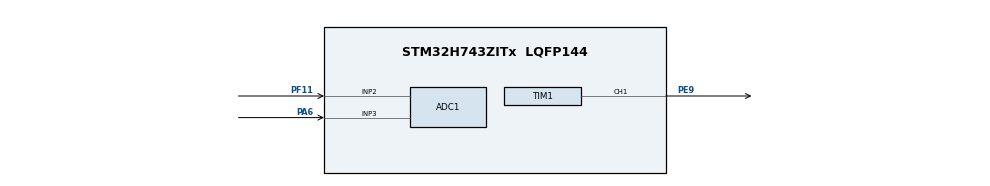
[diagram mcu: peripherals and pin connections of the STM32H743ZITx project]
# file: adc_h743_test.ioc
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ADC1.Channel-0\#ChannelRegularConversion=ADC_CHANNEL_2
ADC1.Channel-1\#ChannelRegularConversion=ADC_CHANNEL_3
ADC1.ContinuousConvMode=ENABLE
ADC1.ConversionDataManagement=ADC_CONVERSIONDATA_DMA_CIRCULAR
ADC1.EOCSelection=ADC_EOC_SEQ_CONV
ADC1.NbrOfConversion=2
ADC1.NbrOfConversionFlag=1
ADC1.OffsetNumber-0\#ChannelRegularConversion=ADC_OFFSET_NONE
ADC1.OffsetNumber-1\#ChannelRegularConversion=ADC_OFFSET_NONE
ADC1.OffsetSignedSaturation-0\#ChannelRegularConversion=DISABLE
ADC1.OffsetSignedSaturation-1\#ChannelRegularConversion=DISABLE
ADC1.Overrun=ADC_OVR_DATA_OVERWRITTEN
ADC1.OversamplingMode=ENABLE
ADC1.Rank-0\#ChannelRegularConversion=1
ADC1.Rank-1\#ChannelRegularConversion=2
ADC1.Ratio=32
ADC1.RightBitShift=ADC_RIGHTBITSHIFT_5
ADC1.SamplingTime-0\#ChannelRegularConversion=ADC_SAMPLETIME_8CYCLES_5
ADC1.SamplingTime-1\#ChannelRegularConversion=ADC_SAMPLETIME_8CYCLES_5
ADC1.master=1
Dma.ADC1.0.Direction=DMA_PERIPH_TO_MEMORY
Dma.ADC1.0.EventEnable=DISABLE
Dma.ADC1.0.FIFOMode=DMA_FIFOMODE_DISABLE
Dma.ADC1.0.Instance=DMA1_Stream1
Dma.ADC1.0.MemDataAlignment=DMA_MDATAALIGN_WORD
Dma.ADC1.0.MemInc=DMA_MINC_ENABLE
Dma.ADC1.0.Mode=DMA_CIRCULAR
Dma.ADC1.0.PeriphDataAlignment=DMA_PDATAALIGN_WORD
Dma.ADC1.0.PeriphInc=DMA_PINC_DISABLE
Dma.ADC1.0.Polarity=HAL_DMAMUX_REQ_GEN_RISING
Dma.ADC1.0.Priority=DMA_PRIORITY_VERY_HIGH
Dma.ADC1.0.RequestNumber=1
Dma.ADC1.0.SignalID=NONE
Dma.ADC1.0.SyncEnable=DISABLE
Dma.ADC1.0.SyncPolarity=HAL_DMAMUX_SYNC_NO_EVENT
Dma.ADC1.0.SyncRequestNumber=1
Dma.ADC1.0.SyncSignalID=NONE
Dma.Request0=ADC1
Mcu.Family=STM32H7
Mcu.Name=STM32H743ZITx
Mcu.Package=LQFP144
NVIC.DMA1_Stream1_IRQn=true\:0\:0\:false\:false\:true\:false\:true
NVIC.PriorityGroup=NVIC_PRIORITYGROUP_4
PA6.Signal=ADCx_INP3
PE9.Signal=S_TIM1_CH1
PF11.Mode=IN2-Single-Ended
PF11.Signal=ADC1_INP2
ProjectManager.HeapSize=0x200
ProjectManager.StackSize=0x400
ProjectManager.TargetToolchain=STM32CubeIDE
RCC.ADCFreq_Value=37500000
RCC.APB1Freq_Value=64000000
RCC.APB2Freq_Value=64000000
RCC.APB3Freq_Value=64000000
RCC.APB4Freq_Value=64000000
RCC.CortexFreq_Value=64000000
RCC.DIVM2=4
RCC.DIVN2=9
RCC.DIVP2=4
RCC.HCLKFreq_Value=64000000
RCC.PLL2FRACN=3072
RCC.SYSCLKFreq_VALUE=64000000
RCC.USBFreq_Value=129000000
SH.ADCx_INP3.0=ADC1_INP3,IN3-Single-Ended
SH.S_TIM1_CH1.0=TIM1_CH1,PWM Generation1 CH1
TIM1.Channel-PWM\ Generation1\ CH1=TIM_CHANNEL_1
TIM1.Period=64000
TIM1.Prescaler=1
TIM1.Pulse-PWM\ Generation1\ CH1=32000
VP_TIM1_VS_ClockSourceINT.Mode=Internal
board=custom

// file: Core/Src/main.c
/* USER CODE BEGIN Header */
/**
 ******************************************************************************
 * @file           : main.c
 * @brief          : Main program body
 ******************************************************************************
 * @attention
 *
 * <h2><center>&copy; Copyright (c) 2022 STMicroelectronics.
 * All rights reserved.</center></h2>
 *
 * This software component is licensed by ST under BSD 3-Clause license,
 * the "License"; You may not use this file except in compliance with the
 * License. You may obtain a copy of the License at:
 *                        opensource.org/licenses/BSD-3-Clause
 *
 ******************************************************************************
 */
/* USER CODE END Header */
#include "main.h"

ADC_HandleTypeDef hadc1;
DMA_HandleTypeDef hdma_adc1;

TIM_HandleTypeDef htim1;

/* USER CODE BEGIN PV */
uint32_t Value [2];
uint32_t Signal = 0;
/* USER CODE END PV */

void SystemClock_Config(void);
static void MX_GPIO_Init(void);
static void MX_TIM1_Init(void);
static void MX_DMA_Init(void);
static void MX_ADC1_Init(void);

int main(void)
{

  /* MCU Configuration--------------------------------------------------------*/

  /* Reset of all peripherals, Initializes the Flash interface and the Systick. */
  HAL_Init();

  /* Configure the system clock */
  SystemClock_Config();

  /* Initialize all configured peripherals */
  MX_GPIO_Init();
  MX_TIM1_Init();
  MX_DMA_Init();
  MX_ADC1_Init();
  /* USER CODE BEGIN 2 */
	HAL_TIM_PWM_Start(&htim1,TIM_CHANNEL_1);
	HAL_ADC_Start_DMA( &hadc1, (uint32_t *) Value, 2);
	HAL_ADCEx_Calibration_Start( &hadc1,   ADC_CALIB_OFFSET,  ADC_SINGLE_ENDED);
  /* USER CODE END 2 */

  /* Infinite loop */
	while (1)
	{

    /* USER CODE BEGIN 3 */

		Signal = Value [0];

	}
  /* USER CODE END 3 */
}

void SystemClock_Config(void)
{
  RCC_OscInitTypeDef RCC_OscInitStruct = {0};
  RCC_ClkInitTypeDef RCC_ClkInitStruct = {0};

  /** Supply configuration update enable
  */
  HAL_PWREx_ConfigSupply(PWR_LDO_SUPPLY);
  /** Configure the main internal regulator output voltage
  */
  __HAL_PWR_VOLTAGESCALING_CONFIG(PWR_REGULATOR_VOLTAGE_SCALE3);

  while(!__HAL_PWR_GET_FLAG(PWR_FLAG_VOSRDY)) {}
  /** Macro to configure the PLL clock source
  */
  __HAL_RCC_PLL_PLLSOURCE_CONFIG(RCC_PLLSOURCE_HSI);
  /** Initializes the RCC Oscillators according to the specified parameters
  * in the RCC_OscInitTypeDef structure.
  */
  RCC_OscInitStruct.OscillatorType = RCC_OSCILLATORTYPE_HSI;
  RCC_OscInitStruct.HSIState = RCC_HSI_DIV1;
  RCC_OscInitStruct.HSICalibrationValue = RCC_HSICALIBRATION_DEFAULT;
  RCC_OscInitStruct.PLL.PLLState = RCC_PLL_NONE;
  RCC_OscInitStruct.PLL.PLLSource = RCC_PLLSOURCE_HSI;
  if (HAL_RCC_OscConfig(&RCC_OscInitStruct) != HAL_OK)
  {
    Error_Handler();
  }
  /** Initializes the CPU, AHB and APB buses clocks
  */
  RCC_ClkInitStruct.ClockType = RCC_CLOCKTYPE_HCLK|RCC_CLOCKTYPE_SYSCLK
                              |RCC_CLOCKTYPE_PCLK1|RCC_CLOCKTYPE_PCLK2
                              |RCC_CLOCKTYPE_D3PCLK1|RCC_CLOCKTYPE_D1PCLK1;
  RCC_ClkInitStruct.SYSCLKSource = RCC_SYSCLKSOURCE_HSI;
  RCC_ClkInitStruct.SYSCLKDivider = RCC_SYSCLK_DIV1;
  RCC_ClkInitStruct.AHBCLKDivider = RCC_HCLK_DIV1;
  RCC_ClkInitStruct.APB3CLKDivider = RCC_APB3_DIV1;
  RCC_ClkInitStruct.APB1CLKDivider = RCC_APB1_DIV1;
  RCC_ClkInitStruct.APB2CLKDivider = RCC_APB2_DIV1;
  RCC_ClkInitStruct.APB4CLKDivider = RCC_APB4_DIV1;

  if (HAL_RCC_ClockConfig(&RCC_ClkInitStruct, FLASH_LATENCY_1) != HAL_OK)
  {
    Error_Handler();
  }
}

static void MX_ADC1_Init(void)
{

  ADC_MultiModeTypeDef multimode = {0};
  ADC_ChannelConfTypeDef sConfig = {0};

  /** Common config
  */
  hadc1.Instance = ADC1;
  hadc1.Init.ClockPrescaler = ADC_CLOCK_ASYNC_DIV1;
  hadc1.Init.Resolution = ADC_RESOLUTION_16B;
  hadc1.Init.ScanConvMode = ADC_SCAN_ENABLE;
  hadc1.Init.EOCSelection = ADC_EOC_SEQ_CONV;
  hadc1.Init.LowPowerAutoWait = DISABLE;
  hadc1.Init.ContinuousConvMode = ENABLE;
  hadc1.Init.NbrOfConversion = 2;
  hadc1.Init.DiscontinuousConvMode = DISABLE;
  hadc1.Init.ExternalTrigConv = ADC_SOFTWARE_START;
  hadc1.Init.ExternalTrigConvEdge = ADC_EXTERNALTRIGCONVEDGE_NONE;
  hadc1.Init.ConversionDataManagement = ADC_CONVERSIONDATA_DMA_CIRCULAR;
  hadc1.Init.Overrun = ADC_OVR_DATA_OVERWRITTEN;
  hadc1.Init.LeftBitShift = ADC_LEFTBITSHIFT_NONE;
  hadc1.Init.OversamplingMode = ENABLE;
  hadc1.Init.Oversampling.Ratio = 32;
  hadc1.Init.Oversampling.RightBitShift = ADC_RIGHTBITSHIFT_5;
  hadc1.Init.Oversampling.TriggeredMode = ADC_TRIGGEREDMODE_SINGLE_TRIGGER;
  hadc1.Init.Oversampling.OversamplingStopReset = ADC_REGOVERSAMPLING_CONTINUED_MODE;
  if (HAL_ADC_Init(&hadc1) != HAL_OK)
  {
    Error_Handler();
  }
  /** Configure the ADC multi-mode
  */
  multimode.Mode = ADC_MODE_INDEPENDENT;
  if (HAL_ADCEx_MultiModeConfigChannel(&hadc1, &multimode) != HAL_OK)
  {
    Error_Handler();
  }
  /** Configure Regular Channel
  */
  sConfig.Channel = ADC_CHANNEL_2;
  sConfig.Rank = ADC_REGULAR_RANK_1;
  sConfig.SamplingTime = ADC_SAMPLETIME_8CYCLES_5;
  sConfig.SingleDiff = ADC_SINGLE_ENDED;
  sConfig.OffsetNumber = ADC_OFFSET_NONE;
  sConfig.Offset = 0;
  sConfig.OffsetSignedSaturation = DISABLE;
  if (HAL_ADC_ConfigChannel(&hadc1, &sConfig) != HAL_OK)
  {
    Error_Handler();
  }
  /** Configure Regular Channel
  */
  sConfig.Channel = ADC_CHANNEL_3;
  sConfig.Rank = ADC_REGULAR_RANK_2;
  if (HAL_ADC_ConfigChannel(&hadc1, &sConfig) != HAL_OK)
  {
    Error_Handler();
  }

}

static void MX_TIM1_Init(void)
{

  TIM_ClockConfigTypeDef sClockSourceConfig = {0};
  TIM_MasterConfigTypeDef sMasterConfig = {0};
  TIM_OC_InitTypeDef sConfigOC = {0};
  TIM_BreakDeadTimeConfigTypeDef sBreakDeadTimeConfig = {0};

  htim1.Instance = TIM1;
  htim1.Init.Prescaler = 1;
  htim1.Init.CounterMode = TIM_COUNTERMODE_UP;
  htim1.Init.Period = 64000;
  htim1.Init.ClockDivision = TIM_CLOCKDIVISION_DIV1;
  htim1.Init.RepetitionCounter = 0;
  htim1.Init.AutoReloadPreload = TIM_AUTORELOAD_PRELOAD_DISABLE;
  if (HAL_TIM_Base_Init(&htim1) != HAL_OK)
  {
    Error_Handler();
  }
  sClockSourceConfig.ClockSource = TIM_CLOCKSOURCE_INTERNAL;
  if (HAL_TIM_ConfigClockSource(&htim1, &sClockSourceConfig) != HAL_OK)
  {
    Error_Handler();
  }
  if (HAL_TIM_PWM_Init(&htim1) != HAL_OK)
  {
    Error_Handler();
  }
  sMasterConfig.MasterOutputTrigger = TIM_TRGO_RESET;
  sMasterConfig.MasterOutputTrigger2 = TIM_TRGO2_RESET;
  sMasterConfig.MasterSlaveMode = TIM_MASTERSLAVEMODE_DISABLE;
  if (HAL_TIMEx_MasterConfigSynchronization(&htim1, &sMasterConfig) != HAL_OK)
  {
    Error_Handler();
  }
  sConfigOC.OCMode = TIM_OCMODE_PWM1;
  sConfigOC.Pulse = 32000;
  sConfigOC.OCPolarity = TIM_OCPOLARITY_HIGH;
  sConfigOC.OCNPolarity = TIM_OCNPOLARITY_HIGH;
  sConfigOC.OCFastMode = TIM_OCFAST_DISABLE;
  sConfigOC.OCIdleState = TIM_OCIDLESTATE_RESET;
  sConfigOC.OCNIdleState = TIM_OCNIDLESTATE_RESET;
  if (HAL_TIM_PWM_ConfigChannel(&htim1, &sConfigOC, TIM_CHANNEL_1) != HAL_OK)
  {
    Error_Handler();
  }
  sBreakDeadTimeConfig.OffStateRunMode = TIM_OSSR_DISABLE;
  sBreakDeadTimeConfig.OffStateIDLEMode = TIM_OSSI_DISABLE;
  sBreakDeadTimeConfig.LockLevel = TIM_LOCKLEVEL_OFF;
  sBreakDeadTimeConfig.DeadTime = 0;
  sBreakDeadTimeConfig.BreakState = TIM_BREAK_DISABLE;
  sBreakDeadTimeConfig.BreakPolarity = TIM_BREAKPOLARITY_HIGH;
  sBreakDeadTimeConfig.BreakFilter = 0;
  sBreakDeadTimeConfig.Break2State = TIM_BREAK2_DISABLE;
  sBreakDeadTimeConfig.Break2Polarity = TIM_BREAK2POLARITY_HIGH;
  sBreakDeadTimeConfig.Break2Filter = 0;
  sBreakDeadTimeConfig.AutomaticOutput = TIM_AUTOMATICOUTPUT_DISABLE;
  if (HAL_TIMEx_ConfigBreakDeadTime(&htim1, &sBreakDeadTimeConfig) != HAL_OK)
  {
    Error_Handler();
  }
  HAL_TIM_MspPostInit(&htim1);

}

static void MX_DMA_Init(void)
{

  /* DMA controller clock enable */
  __HAL_RCC_DMA1_CLK_ENABLE();

  /* DMA interrupt init */
  /* DMA1_Stream1_IRQn interrupt configuration */
  HAL_NVIC_SetPriority(DMA1_Stream1_IRQn, 0, 0);
  HAL_NVIC_EnableIRQ(DMA1_Stream1_IRQn);

}

static void MX_GPIO_Init(void)
{

  /* GPIO Ports Clock Enable */
  __HAL_RCC_GPIOA_CLK_ENABLE();
  __HAL_RCC_GPIOF_CLK_ENABLE();
  __HAL_RCC_GPIOE_CLK_ENABLE();

}

void Error_Handler(void)
{
	__disable_irq();
	while (1)
	{
	}
}

/************************ (C) COPYRIGHT STMicroelectronics *****END OF FILE****/
